AUTOSAR XML (schema 314)
package /ComponentType
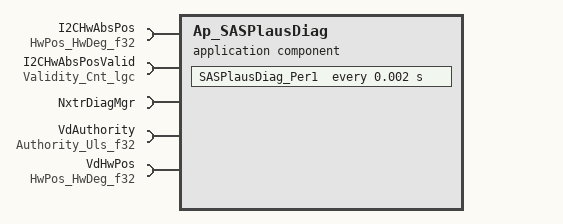
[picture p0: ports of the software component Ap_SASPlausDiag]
  application software component type Ap_SASPlausDiag
    5 x require port:
      I2CHwAbsPos: unqueued-receiver-com-spec{data-element=HwDeg_f32, init-value=D_ZERO_ULS_F32}, required-interface=HwPos_HwDeg_f32
      I2CHwAbsPosValid: unqueued-receiver-com-spec{data-element=Cnt_lgc, init-value=D_FALSE_CNT_LGC}, required-interface=Validity_Cnt_lgc
      NxtrDiagMgr: required-com-specs=[GetNTCActive, GetNTCFailed, GetNTCStatus, SetNTCStatus], required-interface=NxtrDiagMgr
      VdAuthority: unqueued-receiver-com-spec{data-element=Uls_f32, init-value=D_ZERO_ULS_F32}, required-interface=Authority_Uls_f32
      VdHwPos: unqueued-receiver-com-spec{data-element=HwDeg_f32, init-value=D_ZERO_ULS_F32}, required-interface=HwPos_HwDeg_f32
  internal behavior Ap_SASPlausDiag_InternalBehavior: component=Ap_SASPlausDiag
    timing event TMT_SASPlausDiag_Per1: start-on-event=SASPlausDiag_Per1, period=0.002
    port-api-options:
      enable-take-address=false, indirect-api=false, port=I2CHwAbsPos
      enable-take-address=false, indirect-api=false, port=I2CHwAbsPosValid
      enable-take-address=false, indirect-api=false, port=NxtrDiagMgr
      enable-take-address=false, indirect-api=false, port=VdAuthority
      enable-take-address=false, indirect-api=false, port=VdHwPos
    runnable SASPlausDiag_Per1
      4 x data read access:
        READ_I2CHwAbsPos_HwDeg_f32: data-element=I2CHwAbsPos.HwDeg_f32
        READ_I2CHwAbsPosValid_Cnt_lgc: data-element=I2CHwAbsPosValid.Cnt_lgc
        READ_VdAuthority_Uls_f32: data-element=VdAuthority.Uls_f32
        READ_VdHwPos_HwDeg_f32: data-element=VdHwPos.HwDeg_f32
      sync call SC_NxtrDiagMgr_SetNTCStatus: operation=NxtrDiagMgr.SetNTCStatus, timeout=0
  swc implementation Ap_SASPlausDiag_Implementation: behavior=Ap_SASPlausDiag_InternalBehavior
    code-descriptors:
      code Code: type=SRC
